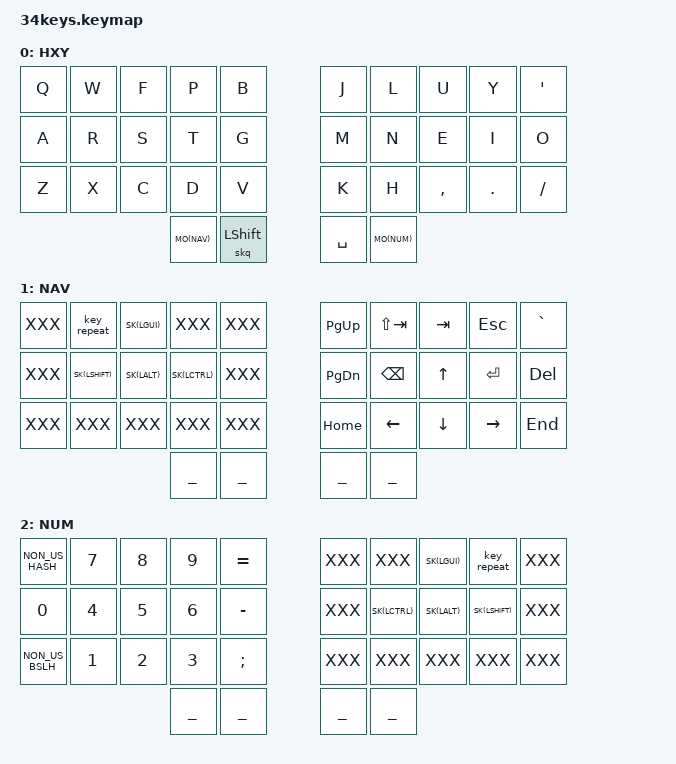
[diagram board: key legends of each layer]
#include <behaviors.dtsi>
#include <dt-bindings/zmk/keys.h>
#include <dt-bindings/zmk/bt.h>
#include <dt-bindings/zmk/outputs.h>
#include "34keys.h"

&sk {
  release-after-ms = <STICKY_KEY_TIMEOUT>;
};

&caps_word {
  continue-list = <UNDERSCORE MINUS BACKSPACE>;
};

&kscan0 {
  debounce-period = <14>;
};

/ {

  combos {
    #include "combos.dtsi"
  };

  macros {
   #include "macros.dtsi"
  };

  behaviors {

    skq: sticky_key_quick_release {
      compatible = "zmk,behavior-sticky-key";
      label = "STICKY_KEY_QUICK_RELEASE";
      #binding-cells = <1>;
      bindings = <&kp>;
      quick-release;
      release-after-ms = <STICKY_KEY_TIMEOUT>;
    };

    // Sticky key on tap, normal key on hold
    // Useful for modifier-clicking without the modifier remaining active
    nk: not_so_sticky_key {
      compatible = "zmk,behavior-hold-tap";
      label = "NOT_SO_STICKY_KEY";
      #binding-cells = <2>;
      tapping_term_ms = <200>;
      flavor = "tap-preferred";
      bindings = <&kp>, <&sk>;
    };

    // A hold-tap that activates without delay (like `&mo`)
    mo_tap: mo_with_tap {
      compatible = "zmk,behavior-hold-tap";
      label = "MO_WITH_TAP";
      #binding-cells = <2>;
      tapping_term_ms = <0>;
      retro-tap;
      flavor = "hold-preferred";
      bindings = <&mo>, <&kp>;
    };

  };

  keymap {
    compatible = "zmk,keymap";

    base_layer {
      label = "HXY";
      bindings = <
        // ╭─────────────┬─────────────┬─────────────┬─────────────┬─────────────╮   ╭─────────────┬─────────────┬─────────────┬─────────────┬─────────────╮
             &kp Q         &kp W         &kp F         &kp P         &kp B             &kp J         &kp L         &kp U         &kp Y         &kp SQT
        // ├─────────────┼─────────────┼─────────────┼─────────────┼─────────────┤   ├─────────────┼─────────────┼─────────────┼─────────────┼─────────────┤
             &kp A         &kp R         &kp S         &kp T         &kp G             &kp M         &kp N         &kp E         &kp I         &kp O
        // ├─────────────┼─────────────┼─────────────┼─────────────┼─────────────┤   ├─────────────┼─────────────┼─────────────┼─────────────┼─────────────┤
             &kp Z         &kp X         &kp C         &kp D         &kp V             &kp K         &kp H         &kp COMMA     &kp DOT       &kp SLASH
        // ╰─────────────┴─────────────┴─────────────┼─────────────┼─────────────┤   ├─────────────┼─────────────┼─────────────┴─────────────┴─────────────╯
                                                       MO(NAV)       &skq LSHIFT       &kp SPACE     MO(NUM)
        //                                           ╰─────────────┴─────────────╯   ╰─────────────┴─────────────╯
      >;
    };

    nav_layer {
      label = "NAV";
      bindings = <
        // ╭─────────────┬─────────────┬─────────────┬─────────────┬─────────────╮   ╭─────────────┬─────────────┬─────────────┬─────────────┬─────────────╮
             XXX           &key_repeat   SK(LGUI)      XXX           XXX               &kp PG_UP     &kp LS(TAB)   &kp TAB       &kp ESC       &kp GRAVE     
        // ├─────────────┼─────────────┼─────────────┼─────────────┼─────────────┤   ├─────────────┼─────────────┼─────────────┼─────────────┼─────────────┤
             XXX           SK(LSHIFT)    SK(LALT)      SK(LCTRL)     XXX               &kp PG_DN     &kp BSPC      &kp UP        &kp ENTER     &kp DEL
        // ├─────────────┼─────────────┼─────────────┼─────────────┼─────────────┤   ├─────────────┼─────────────┼─────────────┼─────────────┼─────────────┤
             XXX           XXX           XXX           XXX           XXX               &kp HOME      &kp LEFT      &kp DOWN      &kp RIGHT     &kp END
        // ╰─────────────┴─────────────┴─────────────┼─────────────┼─────────────┤   ├─────────────┼─────────────┼─────────────┴─────────────┴─────────────╯
                                                       ___           ___               ___           ___
        //                                           ╰─────────────┴─────────────╯   ╰─────────────┴─────────────╯
      >;
    };

    num_layer {
      label = "NUM";
      bindings = <
        // ╭─────────────┬─────────────┬─────────────┬─────────────┬─────────────╮   ╭─────────────┬─────────────┬─────────────┬─────────────┬─────────────╮
             &kp NON_US_HASH  &kp N7     &kp N8        &kp N9        &kp EQUAL         XXX           XXX           SK(LGUI)      &key_repeat   XXX
        // ├─────────────┼─────────────┼─────────────┼─────────────┼─────────────┤   ├─────────────┼─────────────┼─────────────┼─────────────┼─────────────┤
             &kp N0        &kp N4        &kp N5        &kp N6        &kp MINUS         XXX           SK(LCTRL)     SK(LALT)      SK(LSHIFT)    XXX
        // ├─────────────┼─────────────┼─────────────┼─────────────┼─────────────┤   ├─────────────┼─────────────┼─────────────┼─────────────┼─────────────┤
             &kp NON_US_BSLH  &kp N1     &kp N2        &kp N3        &kp SEMI          XXX           XXX           XXX           XXX           XXX
        // ╰─────────────┴─────────────┴─────────────┼─────────────┼─────────────┤   ├─────────────┼─────────────┼─────────────┴─────────────┴─────────────╯
                                                       ___           ___               ___           ___
        //                                           ╰─────────────┴─────────────╯   ╰─────────────┴─────────────╯
      >;
    };

  };
};

